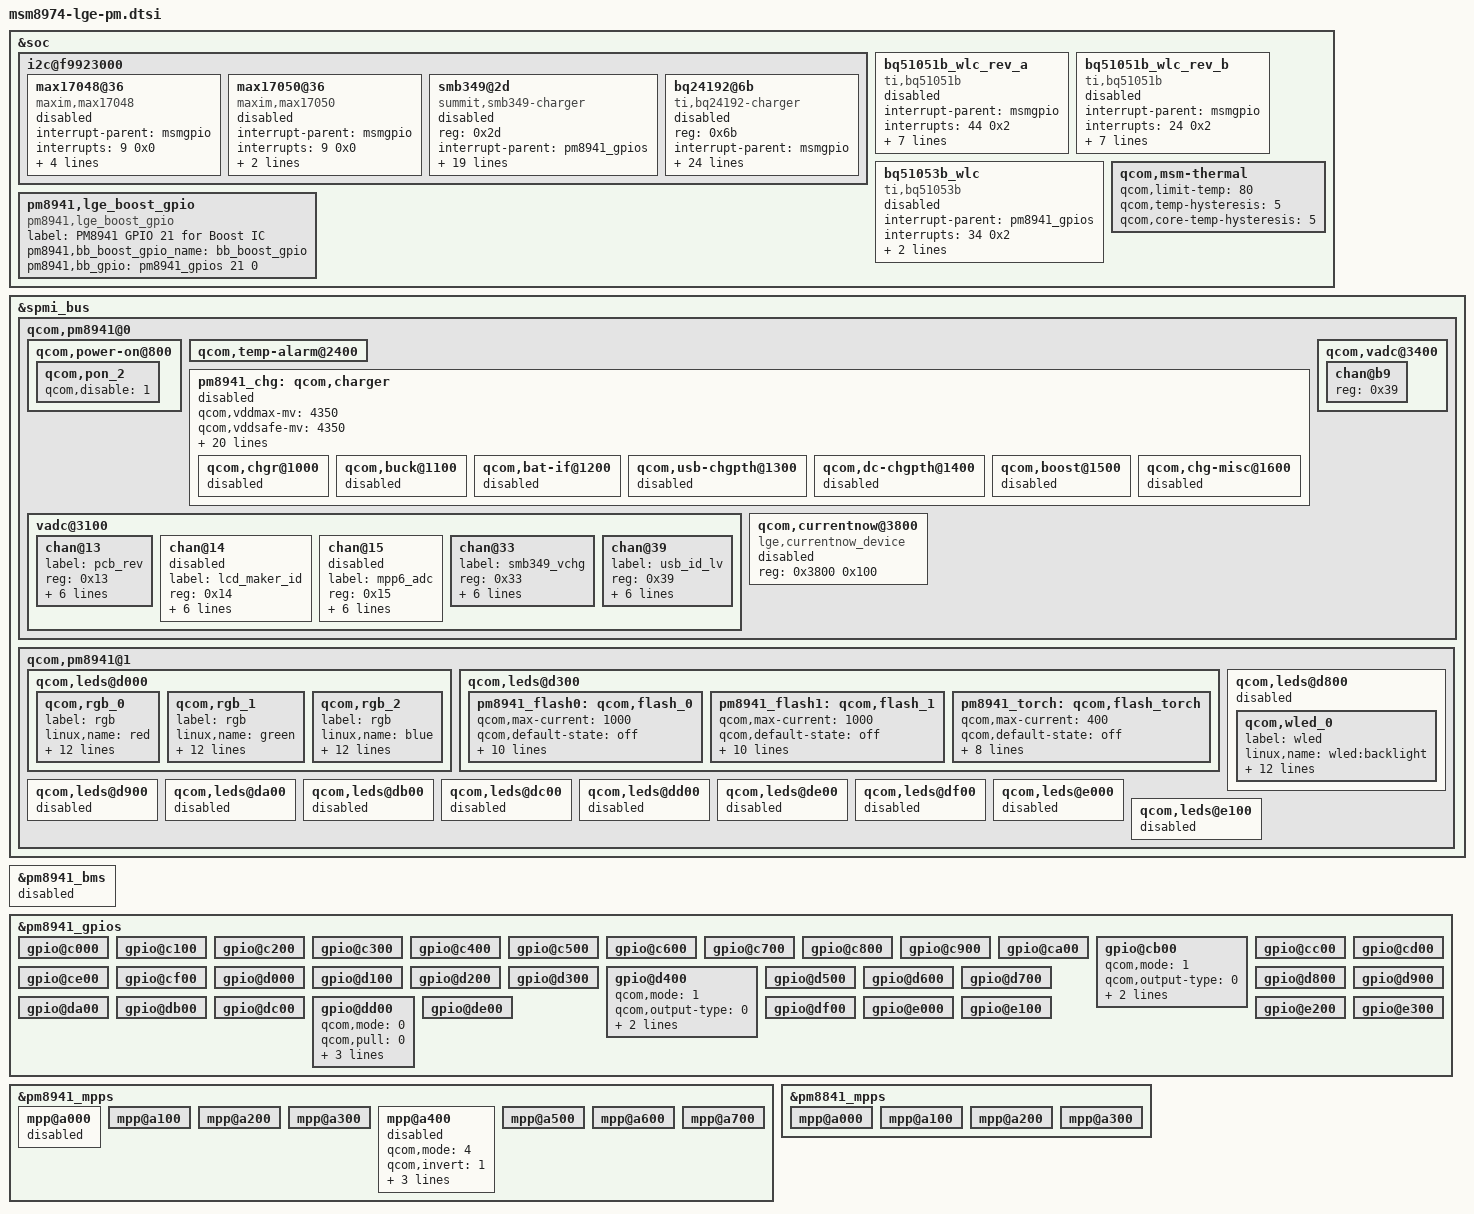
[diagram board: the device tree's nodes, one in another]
/* Copyright (c) 2013, LGE Electronics. All rights reserved.
 *
 * This program is free software; you can redistribute it and/or modify
 * it under the terms of the GNU General Public License version 2 and
 * only version 2 as published by the Free Software Foundation.
 *
 * This program is distributed in the hope that it will be useful,
 * but WITHOUT ANY WARRANTY; without even the implied warranty of
 * MERCHANTABILITY or FITNESS FOR A PARTICULAR PURPOSE.  See the
 * GNU General Public License for more details.
 */

&soc {
	i2c@f9923000 {
		max17048@36 {
			compatible = "maxim,max17048";
			status = "disabled";
			interrupt-parent = <&msmgpio>;
			interrupts = <9 0x0>;
			reg = <0x36>;
			max17048,alert_gpio = <&msmgpio 9 0x00>;
			max17048,alert_threshold = <2>;
			max17048,full_design = <2540>;
		};

		max17050@36 {
			compatible = "maxim,max17050";
			status = "disabled";
			interrupt-parent = <&msmgpio>;
			interrupts = <9 0x0>;
			reg = <0x36>;
			max17048,full_design = <3000>;
		};

		smb349@2d {
			compatible = "summit,smb349-charger";
			reg = <0x2d>; /* 0x5A/0x5B */
			status = "disabled";
			interrupt-parent = <&pm8941_gpios>;
			interrupts = <30 0x2>;
			summit,stat-gpio = <&pm8941_gpios 30 0x02>;
			summit,chg-current-ma = <1200>;
			summit,term-current-ma = <100>;

			lge,no-init-cable = <0 0 0>;
			lge,cable-mhl-1k = <5000 500 500>;
			lge,cable-u-28p7k = <5500 1200 500>;
			lge,cable-28p7k = <6000 1200 500>;
			lge,cable-56k = <200000 1500 1500>;
			lge,cable-100k = <239000 1200 500>;
			lge,cable-130k = <340000 1500 1500>;
			lge,cable-180k = <400000 1200 500>;
			lge,cable-200k = <410000 1200 500>;
			lge,cable-220k = <485000 1200 500>;
			lge,cable-270k = <560000 1200 500>;
			lge,cable-330k = <735000 1200 500>;
			lge,cable-620k = <955000 1200 500>;
			lge,cable-910k = <1140000 1500 1500>;
			lge,cable-none = <1900000 1200  500>;
		};

		bq24192@6b {
			compatible = "ti,bq24192-charger";
			status = "disabled";
			reg = <0x6b>;
			interrupt-parent = <&msmgpio>;
			interrupts = <74 0x2>;
			ti,int-gpio = <&msmgpio 74 0x02>;
			ti,chg-current-ma = <1200>;
			ti,term-current-ma = <256>;
			ti,vbat-max-mv = <4352>;
			ti,pre-chg-current-ma = <256>;
			ti,sys-vmin-mv = <3500>;
			ti,vin-limit-mv = <4360>;
			ti,icl-vbus-mv = <4400>;

			lge,no-init-cable = <0 0 0>;
			lge,cable-mhl-1k = <5000 500 500>;
			lge,cable-u-28p7k = <5500 1200 500>;
			lge,cable-28p7k = <6000 1200 500>;
			lge,cable-56k = <200000 1500 1500>;
			lge,cable-100k = <239000 1200 500>;
			lge,cable-130k = <340000 1500 1500>;
			lge,cable-180k = <400000 1200 500>;
			lge,cable-200k = <410000 1200 500>;
			lge,cable-220k = <485000 1200 500>;
			lge,cable-270k = <560000 1200 500>;
			lge,cable-330k = <735000 1200 500>;
			lge,cable-620k = <955000 1200 500>;
			lge,cable-910k = <1140000 1500 1500>;
			lge,cable-none = <1900000 1200	500>;
		};
	};

	bq51051b_wlc_rev_a {
		compatible = "ti,bq51051b";
		status = "disable";
		interrupt-parent = <&msmgpio>;
		interrupts = <44 0x2>;
		chg_ctrl_gpio = <&pm8941_gpios 23 0x0>;
		active_n_gpio = <&pm8941_gpios 24 0x0>;
		half_chg_ctrl_gpio = <&pm8941_gpios 25 0x0>;
		otg_ctrl_gpio = <&pm8941_gpios 35 0x0>;
		wlc_ts_mpp = <&pm8941_mpps 7 0x0>;
		track_gpio = <&msmgpio 44 0x00>;
		revision = "...rev_a";
	};

	bq51051b_wlc_rev_b {
		compatible = "ti,bq51051b";
		status = "disable";
		interrupt-parent = <&msmgpio>;
		interrupts = <24 0x2>;
		chg_ctrl_gpio = <&pm8941_gpios 23 0x0>;
		active_n_gpio = <&pm8941_gpios 24 0x0>;
		half_chg_ctrl_gpio = <&pm8941_gpios 25 0x0>;
		otg_ctrl_gpio = <&pm8941_gpios 35 0x0>;
		wlc_ts_mpp = <&pm8941_mpps 7 0x0>;
		track_gpio = <&msmgpio 24 0x00>;
		revision = "rev_b...";
    };

	bq51053b_wlc {
		compatible = "ti,bq51053b";
		status = "disable";
		interrupt-parent = <&pm8941_gpios>;
		interrupts = <34 0x2>;
		wlc_int_gpio = <&pm8941_gpios 34 0x2>;
		wlc_full_chg = <&pm8941_gpios 36 0x0>;
	};

	qcom,msm-thermal {
		qcom,limit-temp = <80>;
		qcom,temp-hysteresis = <5>;
		qcom,core-temp-hysteresis = <5>;
	};

	pm8941,lge_boost_gpio {
		compatible = "pm8941,lge_boost_gpio";
		label = "PM8941 GPIO 21 for Boost IC";
		status = "ok";
		pm8941,bb_boost_gpio_name = "bb_boost_gpio";
		pm8941,bb_gpio = <&pm8941_gpios 21 0>;
	};

};

&spmi_bus {
	qcom,pm8941@0 {
		qcom,power-on@800 {
			qcom,pon_2 {
				qcom,disable = <1>;
			};
		};

		qcom,temp-alarm@2400 {

		};

		pm8941_chg: qcom,charger {
			status = "disabled";

			qcom,vddmax-mv = <4350>;
			qcom,vddsafe-mv = <4350>;
			qcom,vinmin-mv = <4350>;
			qcom,vbatdet-mv = <4100>;
			qcom,ibatmax-ma = <1500>;
			qcom,ibatterm-ma = <200>;
			qcom,ibatsafe-ma = <1500>;

			/* Cable type definition.
			* Each cable type has 3 values
			* that we can configure the threshold of ADC value and TA/USB IUSB max current value.
			* ex)
			*    cable type = <adc_threshold, TA_MA, USB_MA>.
			*/

			lge,no-init-cable = <0 0 0>;
			lge,cable-mhl-1k = <5000 500 500>;
			lge,cable-u-28p7k = <5500 500 500>;
			lge,cable-28p7k = <6000 500 500>;
			lge,cable-56k = <200000 1500 1500>;
			lge,cable-100k = <239000 500 500>;
			lge,cable-130k = <340000 1500 1500>;
			lge,cable-180k = <400000 700 500>;
			lge,cable-200k = <410000 700 500>;
			lge,cable-220k = <485000 900 500>;
			lge,cable-270k = <560000 900 500>;
			lge,cable-330k = <735000 500 500>;
			lge,cable-620k = <955000 500 500>;
			lge,cable-910k = <1140000 1500 1500>;
			lge,cable-none = <1900000 900  500>;

			qcom,chgr@1000 {
				status = "disabled";
			};

			qcom,buck@1100 {
				status = "disabled";
			};

			qcom,bat-if@1200 {
				status = "disabled";
			};

			qcom,usb-chgpth@1300 {
				status = "disabled";
			};

			qcom,dc-chgpth@1400 {
				status = "disabled";
			};

			qcom,boost@1500 {
				status = "disabled";
			};

			qcom,chg-misc@1600 {
				status = "disabled";
			};

		};

		vadc@3100 {
			chan@13 {
				label = "pcb_rev";
				reg = <0x13>;
				qcom,decimation = <0>;
				qcom,pre-div-channel-scaling = <0>;
				qcom,calibration-type = "absolute";
				qcom,scale-function = <0>;
				qcom,hw-settle-time = <0>;
				qcom,fast-avg-setup = <0>;
			};

			chan@14 {
				status = "disable";
				label = "lcd_maker_id";
				reg = <0x14>;
				qcom,decimation = <0>;
				qcom,pre-div-channel-scaling = <0>;
				qcom,calibration-type = "absolute";
				qcom,scale-function = <0>;
				qcom,hw-settle-time = <0>;
				qcom,fast-avg-setup = <0>;
			};

			chan@15 {
				status = "disable";
				label="mpp6_adc";
				reg = <0x15>;
				qcom,decimation = <0>;
				qcom,pre-div-channel-scaling = <0>;
				qcom,calibration-type = "absolute";
				qcom,scale-function = <0>;
				qcom,hw-settle-time = <0>;
				qcom,fast-avg-setup = <0>;
			};

			chan@33 {
				label = "smb349_vchg";
				reg = <0x33>;
				qcom,decimation = <0>;
				qcom,pre-div-channel-scaling = <0>;
				qcom,calibration-type = "absolute";
				qcom,scale-function = <0>;
				qcom,hw-settle-time = <0>;
				qcom,fast-avg-setup = <0>;
			};

			chan@39 {
				label = "usb_id_lv";
				reg = <0x39>;
				qcom,decimation = <0>;
				qcom,pre-div-channel-scaling = <0>;
				qcom,calibration-type = "absolute";
				qcom,scale-function = <0>;
				qcom,hw-settle-time = <0>;
				qcom,fast-avg-setup = <0>;
			};
		};

		qcom,vadc@3400 {
			chan@b9 {
				reg = <0x39>;
			};
		};

		qcom,currentnow@3800 {
			compatible ="lge,currentnow_device";
			reg = <0x3800 0x100>;
			status = "disable";
		};
	};

	qcom,pm8941@1 {
		qcom,leds@d000 {
			status = "okay";
			qcom,rgb_0 {
				label = "rgb";
				linux,name = "red";
				qcom,mode = "lpg";
				qcom,pwm-channel = <6>;
				qcom,pwm-us = <5000>;
				qcom,duty-ms = <70>;
				qcom,start-idx = <0>;
				qcom,idx-len = <63>;
				qcom,duty-pcts = [
					 00 09 09 00 00
					 00 00 00 15 2A
					 3F 2A 15 00 00
					 00 00 00 00 00
					 00 00 2C 57 5E
					 64 63 63 63 62
					 60 5F 5D 5A 58
					 53 4F 4A 41 37
					 2D 17 00 00 00
					 22 43 2C 16 00
					 00 00 00 00 00
					 09 10 21 31 21
					 10 09 00
					 ];
				qcom,max-current = <12>;
				qcom,default-state = "off";
				qcom,id = <3>;
				linux,default-trigger = "none";
			};

			qcom,rgb_1 {
				label = "rgb";
				linux,name = "green";
				qcom,mode = "lpg";
				qcom,pwm-channel = <5>;
				qcom,pwm-us = <5000>;
				qcom,duty-ms = <70>;
				qcom,start-idx = <0>;
				qcom,idx-len = <63>;
				qcom,duty-pcts = [
					 00 09 09 00 00
					 00 00 00 15 2A
					 3F 2A 15 00 00
					 00 00 00 00 00
					 00 00 2C 57 5E
					 64 63 63 63 62
					 60 5F 5D 5A 58
					 53 4F 4A 41 37
					 2D 17 00 00 00
					 22 43 2C 16 00
					 00 00 00 00 00
					 09 10 21 31 21
					 10 09 00
					 ];
				qcom,max-current = <12>;
				qcom,default-state = "off";
				qcom,id = <4>;
				linux,default-trigger = "none";
			};

			qcom,rgb_2 {
				label = "rgb";
				linux,name = "blue";
				qcom,mode = "lpg";
				qcom,pwm-channel = <4>;
				qcom,pwm-us = <5000>;
				qcom,duty-ms = <70>;
				qcom,start-idx = <0>;
				qcom,idx-len = <63>;
				qcom,duty-pcts = [
					 00 09 09 00 00
					 00 00 00 15 2A
					 3F 2A 15 00 00
					 00 00 00 00 00
					 00 00 2C 57 5E
					 64 63 63 63 62
					 60 5F 5D 5A 58
					 53 4F 4A 41 37
					 2D 17 00 00 00
					 22 43 2C 16 00
					 00 00 00 00 00
					 09 10 21 31 21
					 10 09 00
					 ];
				qcom,max-current = <12>;
				qcom,default-state = "off";
				qcom,id = <5>;
				linux,default-trigger = "none";
			};
		};

		qcom,leds@d300 {
			status = "okay";
			pm8941_flash0: qcom,flash_0 {
				qcom,max-current = <1000>;
				qcom,default-state = "off";
				qcom,headroom = <3>;
				qcom,duration = <1280>;
				qcom,clamp-curr = <200>;
				qcom,startup-dly = <3>;
				qcom,safety-timer;
				label = "flash";
				linux,default-trigger =
					"flash0_trigger";
				qcom,id = <1>;
				linux,name = "led:flash_0";
				qcom,current = <600>;
			};

			pm8941_flash1: qcom,flash_1 {
				qcom,max-current = <1000>;
				qcom,default-state = "off";
				qcom,headroom = <3>;
				qcom,duration = <1280>;
				qcom,clamp-curr = <200>;
				qcom,startup-dly = <3>;
				qcom,safety-timer;
				linux,default-trigger =
					"flash1_trigger";
				label = "flash";
				qcom,id = <2>;
				linux,name = "led:flash_1";
				qcom,current = <600>;
			};

			pm8941_torch: qcom,flash_torch {
				qcom,max-current = <400>;
				qcom,default-state = "off";
				qcom,headroom = <3>;
				qcom,startup-dly = <3>;
				linux,default-trigger =
					"torch_trigger";
				label = "flash";
				qcom,id = <2>;
				linux,name = "led:flash_torch";
				qcom,current = <180>;
				qcom,torch-enable;
			};
		};

		qcom,leds@d800 {
			status = "disable";
			qcom,wled_0 {
				label = "wled";
				linux,name = "wled:backlight";
				linux,default-trigger = "bkl-trigger";
				qcom,cs-out-en;
				qcom,op-fdbck = <1>;
				qcom,default-state = "off";
				qcom,max-current = <25>;
				qcom,ctrl-delay-us = <0>;
				qcom,boost-curr-lim = <3>;
				qcom,cp-sel = <0>;
				qcom,switch-freq = <2>;
				qcom,ovp-val = <2>;
				qcom,num-strings = <1>;
				qcom,id = <0>;
			};
		};

		qcom,leds@d900 {
			status = "disabled";
		};

		qcom,leds@da00 {
			status = "disabled";
		};

		qcom,leds@db00 {
			status = "disabled";
		};

		qcom,leds@dc00 {
			status = "disabled";
		};

		qcom,leds@dd00 {
			status = "disabled";
		};

		qcom,leds@de00 {
			status = "disabled";
		};

		qcom,leds@df00 {
			status = "disabled";
		};

		qcom,leds@e000 {
			status = "disabled";
		};

		qcom,leds@e100 {
			status = "disabled";
		};
	};

};

&pm8941_bms {
	status = "disable";
};

&pm8941_gpios {
	gpio@c000 { /* GPIO 1 */
	};

	gpio@c100 { /* GPIO 2 */
	};

	gpio@c200 { /* GPIO 3 */
	};

	gpio@c300 { /* GPIO 4 */
	};

	gpio@c400 { /* GPIO 5 */
	};

	gpio@c500 { /* GPIO 6 */
	};

	gpio@c600 { /* GPIO 7 */
	};

	gpio@c700 { /* GPIO 8 */
	};

	gpio@c800 { /* GPIO 9 */
	};

	gpio@c900 { /* GPIO 10 */
	};

	gpio@ca00 { /* GPIO 11 */
	};

	gpio@cb00 { /* GPIO 12 */
		status = "ok";
		qcom,mode = <1>;
		qcom,output-type = <0>;
		qcom,pull = <4>;
		qcom,src-sel = <0>;
	};

	gpio@cc00 { /* GPIO 13 */
	};

	gpio@cd00 { /* GPIO 14 */
	};

	gpio@ce00 { /* GPIO 15 */
	};

	gpio@cf00 { /* GPIO 16 */
	};

	gpio@d000 { /* GPIO 17 */
	};

	gpio@d100 { /* GPIO 18 */
	};

	gpio@d200 { /* GPIO 19 */
	};

	gpio@d300 { /* GPIO 20 */
	};

	gpio@d400 { /* GPIO 21 */
		status = "ok";
		qcom,mode = <1>;
		qcom,output-type = <0>;
		qcom,pull = <4>;
		qcom,src-sel = <0>;
	};

	gpio@d500 { /* GPIO 22 */
	};

	gpio@d600 { /* GPIO 23 */
	};

	gpio@d700 { /* GPIO 24 */
	};

	gpio@d800 { /* GPIO 25 */
	};

	gpio@d900 { /* GPIO 26 */
	};

	gpio@da00 { /* GPIO 27 */
	};

	gpio@db00 { /* GPIO 28 */
	};

	gpio@dc00 { /* GPIO 29 */
	};

	gpio@dd00 { /* GPIO 30 */
		status = "ok";
		qcom,mode = <0>;		/* QPNP_PIN_MODE_DIG_IN */
		qcom,pull = <0>;		/* pull-up */
		qcom,master-en = <1>;		/* Enable Module */
		qcom,src-select = <0>;		/* QPNP_PIN_SEL_FUNC_CONSTANT */
		qcom,vin-sel = <2>;		/* Select 1.8V Source */
	};

	gpio@de00 { /* GPIO 31 */
	};

	gpio@df00 { /* GPIO 32 */
	};

	gpio@e000 { /* GPIO 33 */
	};

	gpio@e100 { /* GPIO 34 */
	};

	gpio@e200 { /* GPIO 35 */
	};

	gpio@e300 { /* GPIO 36 */
	};
};

&pm8941_mpps {

	mpp@a000 { /* MPP 1 */
		status = "disable";
	};

	mpp@a100 { /* MPP 2 */
	};

	mpp@a200 { /* MPP 3 */
	};

	mpp@a300 { /* MPP 4 */
	};

	mpp@a400 { /* MPP 5 */
		status = "disable";
		qcom,mode = <4>; /* AIN input */
		qcom,invert = <1>; /* Enable MPP */
		qcom,src-sel = <0>; /* CONSTANT */
		qcom,master-en = <1>; /* ENABLE MPP */
		qcom,ain-route = <0>;
	};

	mpp@a500 { /* MPP 6 */
	};

	mpp@a600 { /* MPP 7 */
	};

	mpp@a700 { /* MPP 8 */
	};
};

&pm8841_mpps {

	mpp@a000 { /* MPP 1 */
	};

	mpp@a100 { /* MPP 2 */
	};

	mpp@a200 { /* MPP 3 */
	};

	mpp@a300 { /* MPP 4 */
	};
};

